AUTOSAR XML (schema 4-0-3)
standard types defined: Boolean, UInt16
package /AUTOSAR_Platform/DataConstrs
  range DC_Boolean: raw 0..1
  range DC_UInt16: raw 0..65535
package /PATAC/MSM/ComponentTypes
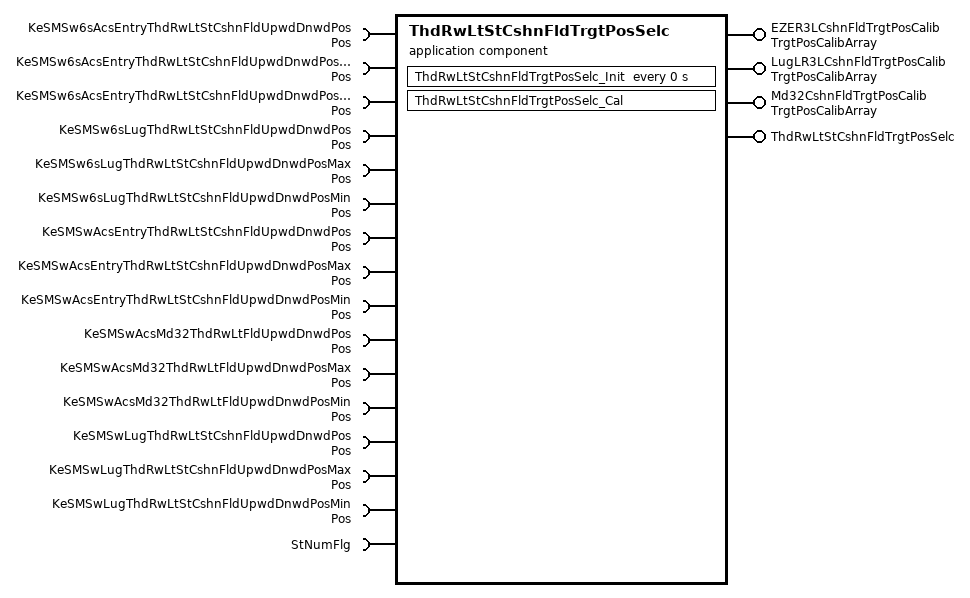
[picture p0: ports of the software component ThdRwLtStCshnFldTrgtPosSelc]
  application sw component type ThdRwLtStCshnFldTrgtPosSelc
    4 x provide port:
      EZER3LCshnFldTrgtPosCalib: nonqueued-sender-com-spec{data-element=TrgtPosArray, init-value=[4095, 4095, 4095]}, provided-interface=TrgtPosCalibArray
      LugLR3LCshnFldTrgtPosCalib: nonqueued-sender-com-spec{data-element=TrgtPosArray, init-value=[4095, 4095, 4095]}, provided-interface=TrgtPosCalibArray
      Md32CshnFldTrgtPosCalib: nonqueued-sender-com-spec{data-element=TrgtPosArray, init-value=[4095, 4095, 4095]}, provided-interface=TrgtPosCalibArray
      ThdRwLtStCshnFldTrgtPosSelc: server-com-spec{operation=Cal, queue-length=1}, provided-interface=ThdRwLtStCshnFldTrgtPosSelc
    16 x require port:
      KeSMSw6sAcsEntryThdRwLtStCshnFldUpwdDnwdPos: parameter-require-com-spec{init-value=0, parameter=Val}, required-interface=Pos
      KeSMSw6sAcsEntryThdRwLtStCshnFldUpwdDnwdPosMax: parameter-require-com-spec{init-value=0, parameter=Val}, required-interface=Pos
      KeSMSw6sAcsEntryThdRwLtStCshnFldUpwdDnwdPosMin: parameter-require-com-spec{init-value=0, parameter=Val}, required-interface=Pos
      KeSMSw6sLugThdRwLtStCshnFldUpwdDnwdPos: parameter-require-com-spec{init-value=30, parameter=Val}, required-interface=Pos
      KeSMSw6sLugThdRwLtStCshnFldUpwdDnwdPosMax: parameter-require-com-spec{init-value=40, parameter=Val}, required-interface=Pos
      KeSMSw6sLugThdRwLtStCshnFldUpwdDnwdPosMin: parameter-require-com-spec{init-value=20, parameter=Val}, required-interface=Pos
      KeSMSwAcsEntryThdRwLtStCshnFldUpwdDnwdPos: parameter-require-com-spec{init-value=0, parameter=Val}, required-interface=Pos
      KeSMSwAcsEntryThdRwLtStCshnFldUpwdDnwdPosMax: parameter-require-com-spec{init-value=0, parameter=Val}, required-interface=Pos
      KeSMSwAcsEntryThdRwLtStCshnFldUpwdDnwdPosMin: parameter-require-com-spec{init-value=0, parameter=Val}, required-interface=Pos
      KeSMSwAcsMd32ThdRwLtFldUpwdDnwdPos: parameter-require-com-spec{init-value=0, parameter=Val}, required-interface=Pos
      KeSMSwAcsMd32ThdRwLtFldUpwdDnwdPosMax: parameter-require-com-spec{init-value=0, parameter=Val}, required-interface=Pos
      KeSMSwAcsMd32ThdRwLtFldUpwdDnwdPosMin: parameter-require-com-spec{init-value=0, parameter=Val}, required-interface=Pos
      KeSMSwLugThdRwLtStCshnFldUpwdDnwdPos: parameter-require-com-spec{init-value=30, parameter=Val}, required-interface=Pos
      KeSMSwLugThdRwLtStCshnFldUpwdDnwdPosMax: parameter-require-com-spec{init-value=40, parameter=Val}, required-interface=Pos
      KeSMSwLugThdRwLtStCshnFldUpwdDnwdPosMin: parameter-require-com-spec{init-value=20, parameter=Val}, required-interface=Pos
      StNumFlg: required-interface=StNumFlg
        required-com-specs:
          data-element=Is4s, filter=data-filter-type=ALWAYS, init-value=0
          data-element=Is6s, filter=data-filter-type=ALWAYS, init-value=0
          data-element=Is6s7s, filter=data-filter-type=ALWAYS, init-value=0
          data-element=Is7s, filter=data-filter-type=ALWAYS, init-value=0
    behavior ThdRwLtStCshnFldTrgtPosSelc_InternalBehavior
      operation invoked event OIT_ThdRwLtStCshnFldTrgtPosSelc_Cal_ThdRwLtStCshnFldTrgtPosSelc_Cal: start-on-event=ThdRwLtStCshnFldTrgtPosSelc_Cal, operation=ThdRwLtStCshnFldTrgtPosSelc.Cal
      timing event ThdRwLtStCshnFldTrgtPosSelc_InitEvent: start-on-event=ThdRwLtStCshnFldTrgtPosSelc_Init, period=0
      runnable ThdRwLtStCshnFldTrgtPosSelc_Cal
        data-receive-point-by-arguments:
          4 x access:
            REC_StNumFlg_Is4s: accessed-variable=StNumFlg.Is4s
            REC_StNumFlg_Is6s: accessed-variable=StNumFlg.Is6s
            REC_StNumFlg_Is6s7s: accessed-variable=StNumFlg.Is6s7s
            REC_StNumFlg_Is7s: accessed-variable=StNumFlg.Is7s
        data-send-points:
          access SEND_EZER3LCshnFldTrgtPosCalib_TrgtPosArray: accessed-variable=EZER3LCshnFldTrgtPosCalib.TrgtPosArray
          access SEND_LugLR3LCshnFldTrgtPosCalib_TrgtPosArray: accessed-variable=LugLR3LCshnFldTrgtPosCalib.TrgtPosArray
          access SEND_Md32CshnFldTrgtPosCalib_TrgtPosArray: accessed-variable=Md32CshnFldTrgtPosCalib.TrgtPosArray
        15 x parameter access:
          PA_KeSMSw6sAcsEntryThdRwLtStCshnFldUpwdDnwdPos_Val: accessed-parameter=KeSMSw6sAcsEntryThdRwLtStCshnFldUpwdDnwdPos.Val
          PA_KeSMSw6sAcsEntryThdRwLtStCshnFldUpwdDnwdPosMax_Val: accessed-parameter=KeSMSw6sAcsEntryThdRwLtStCshnFldUpwdDnwdPosMax.Val
          PA_KeSMSw6sAcsEntryThdRwLtStCshnFldUpwdDnwdPosMin_Val: accessed-parameter=KeSMSw6sAcsEntryThdRwLtStCshnFldUpwdDnwdPosMin.Val
          PA_KeSMSw6sLugThdRwLtStCshnFldUpwdDnwdPos_Val: accessed-parameter=KeSMSw6sLugThdRwLtStCshnFldUpwdDnwdPos.Val
          PA_KeSMSw6sLugThdRwLtStCshnFldUpwdDnwdPosMax_Val: accessed-parameter=KeSMSw6sLugThdRwLtStCshnFldUpwdDnwdPosMax.Val
          PA_KeSMSw6sLugThdRwLtStCshnFldUpwdDnwdPosMin_Val: accessed-parameter=KeSMSw6sLugThdRwLtStCshnFldUpwdDnwdPosMin.Val
          PA_KeSMSwAcsEntryThdRwLtStCshnFldUpwdDnwdPos_Val: accessed-parameter=KeSMSwAcsEntryThdRwLtStCshnFldUpwdDnwdPos.Val
          PA_KeSMSwAcsEntryThdRwLtStCshnFldUpwdDnwdPosMax_Val: accessed-parameter=KeSMSwAcsEntryThdRwLtStCshnFldUpwdDnwdPosMax.Val
          PA_KeSMSwAcsEntryThdRwLtStCshnFldUpwdDnwdPosMin_Val: accessed-parameter=KeSMSwAcsEntryThdRwLtStCshnFldUpwdDnwdPosMin.Val
          PA_KeSMSwAcsMd32ThdRwLtFldUpwdDnwdPos_Val: accessed-parameter=KeSMSwAcsMd32ThdRwLtFldUpwdDnwdPos.Val
          PA_KeSMSwAcsMd32ThdRwLtFldUpwdDnwdPosMax_Val: accessed-parameter=KeSMSwAcsMd32ThdRwLtFldUpwdDnwdPosMax.Val
          PA_KeSMSwAcsMd32ThdRwLtFldUpwdDnwdPosMin_Val: accessed-parameter=KeSMSwAcsMd32ThdRwLtFldUpwdDnwdPosMin.Val
          PA_KeSMSwLugThdRwLtStCshnFldUpwdDnwdPos_Val: accessed-parameter=KeSMSwLugThdRwLtStCshnFldUpwdDnwdPos.Val
          PA_KeSMSwLugThdRwLtStCshnFldUpwdDnwdPosMax_Val: accessed-parameter=KeSMSwLugThdRwLtStCshnFldUpwdDnwdPosMax.Val
          PA_KeSMSwLugThdRwLtStCshnFldUpwdDnwdPosMin_Val: accessed-parameter=KeSMSwLugThdRwLtStCshnFldUpwdDnwdPosMin.Val
      runnable ThdRwLtStCshnFldTrgtPosSelc_Init
        15 x parameter access:
          PA_KeSMSw6sAcsEntryThdRwLtStCshnFldUpwdDnwdPos_Val: accessed-parameter=KeSMSw6sAcsEntryThdRwLtStCshnFldUpwdDnwdPos.Val
          PA_KeSMSw6sAcsEntryThdRwLtStCshnFldUpwdDnwdPosMax_Val: accessed-parameter=KeSMSw6sAcsEntryThdRwLtStCshnFldUpwdDnwdPosMax.Val
          PA_KeSMSw6sAcsEntryThdRwLtStCshnFldUpwdDnwdPosMin_Val: accessed-parameter=KeSMSw6sAcsEntryThdRwLtStCshnFldUpwdDnwdPosMin.Val
          PA_KeSMSw6sLugThdRwLtStCshnFldUpwdDnwdPos_Val: accessed-parameter=KeSMSw6sLugThdRwLtStCshnFldUpwdDnwdPos.Val
          PA_KeSMSw6sLugThdRwLtStCshnFldUpwdDnwdPosMax_Val: accessed-parameter=KeSMSw6sLugThdRwLtStCshnFldUpwdDnwdPosMax.Val
          PA_KeSMSw6sLugThdRwLtStCshnFldUpwdDnwdPosMin_Val: accessed-parameter=KeSMSw6sLugThdRwLtStCshnFldUpwdDnwdPosMin.Val
          PA_KeSMSwAcsEntryThdRwLtStCshnFldUpwdDnwdPos_Val: accessed-parameter=KeSMSwAcsEntryThdRwLtStCshnFldUpwdDnwdPos.Val
          PA_KeSMSwAcsEntryThdRwLtStCshnFldUpwdDnwdPosMax_Val: accessed-parameter=KeSMSwAcsEntryThdRwLtStCshnFldUpwdDnwdPosMax.Val
          PA_KeSMSwAcsEntryThdRwLtStCshnFldUpwdDnwdPosMin_Val: accessed-parameter=KeSMSwAcsEntryThdRwLtStCshnFldUpwdDnwdPosMin.Val
          PA_KeSMSwAcsMd32ThdRwLtFldUpwdDnwdPos_Val: accessed-parameter=KeSMSwAcsMd32ThdRwLtFldUpwdDnwdPos.Val
          PA_KeSMSwAcsMd32ThdRwLtFldUpwdDnwdPosMax_Val: accessed-parameter=KeSMSwAcsMd32ThdRwLtFldUpwdDnwdPosMax.Val
          PA_KeSMSwAcsMd32ThdRwLtFldUpwdDnwdPosMin_Val: accessed-parameter=KeSMSwAcsMd32ThdRwLtFldUpwdDnwdPosMin.Val
          PA_KeSMSwLugThdRwLtStCshnFldUpwdDnwdPos_Val: accessed-parameter=KeSMSwLugThdRwLtStCshnFldUpwdDnwdPos.Val
          PA_KeSMSwLugThdRwLtStCshnFldUpwdDnwdPosMax_Val: accessed-parameter=KeSMSwLugThdRwLtStCshnFldUpwdDnwdPosMax.Val
          PA_KeSMSwLugThdRwLtStCshnFldUpwdDnwdPosMin_Val: accessed-parameter=KeSMSwLugThdRwLtStCshnFldUpwdDnwdPosMin.Val
  swc implementation ThdRwLtStCshnFldTrgtPosSelc_Implementation: behavior=ThdRwLtStCshnFldTrgtPosSelc_InternalBehavior
    code-descriptors:
      code Default: artifact-descriptors=autosar-engineering-object={short-label=Default, category=SWSRC}
package /PATAC/MSM/ModeAdjust/CalPortInterface
  parameter interface Pos
    parameter data prototype Val: sw-calibration-access=READ-WRITE, type=UInt16
package /PATAC/MSM/ModeAdjust/DataType
  impl type TrgtPosCalibArray: category=ARRAY, sw-calibration-access=READ-ONLY, type-emitter=RTE  # 0:pos 1:max 2:min
    element Element: array-size=3, array-size-semantics=FIXED-SIZE, implementation-data-type=UInt16, invalid-value=0
package /PATAC/MSM/ModeAdjust/PortInterface
  client server interface ThdRwLtStCshnFldTrgtPosSelc
    operation Cal
  sender receiver interface StNumFlg
    4 x data, all with type=Boolean:
      Is4s
      Is6s
      Is6s7s
      Is7s
    invalidation-policys:
      data-element=Is4s, handle-invalid=DONT-INVALIDATE
      data-element=Is6s, handle-invalid=DONT-INVALIDATE
      data-element=Is6s7s, handle-invalid=DONT-INVALIDATE
      data-element=Is7s, handle-invalid=DONT-INVALIDATE
  sender receiver interface TrgtPosCalibArray: invalidation-policy{data-element=TrgtPosArray, handle-invalid=DONT-INVALIDATE}
    data TrgtPosArray: type=TrgtPosCalibArray  # 0:Pos 1:Max 2:Min
